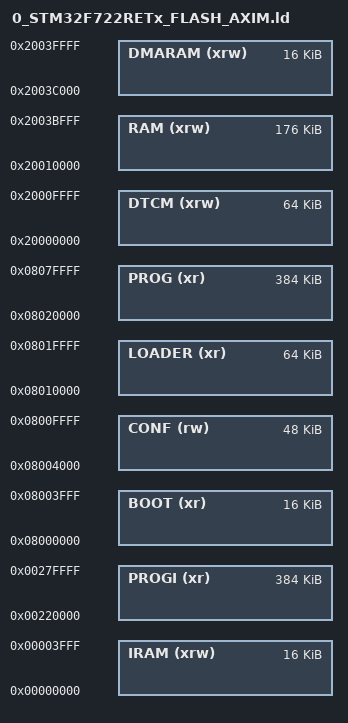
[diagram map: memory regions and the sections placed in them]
/* Specify the memory areas */
MEMORY
{
    IRAM(xrw)   : ORIGIN = 0x00000000, LENGTH = 16k
    DTCM(xrw)   : ORIGIN = 0x20000000, LENGTH = 64k
    RAM(xrw)    : ORIGIN = 0x20010000, LENGTH = 176k
    DMARAM(xrw) : ORIGIN = 0x2003c000, LENGTH = 16k

    BOOT(xr)	: ORIGIN = 0x08000000, LENGTH = 16k
    CONF(rw)	: ORIGIN = 0x08004000, LENGTH = 48k
    LOADER(xr)	: ORIGIN = 0x08010000, LENGTH = 64k
    PROGI(xr)	: ORIGIN = 0x00220000, LENGTH = 384k
    PROG(xr)	: ORIGIN = 0x08020000, LENGTH = 384k
}

REGION_ALIAS("TEXT", PROG);
REGION_ALIAS("LOAD", PROG);
